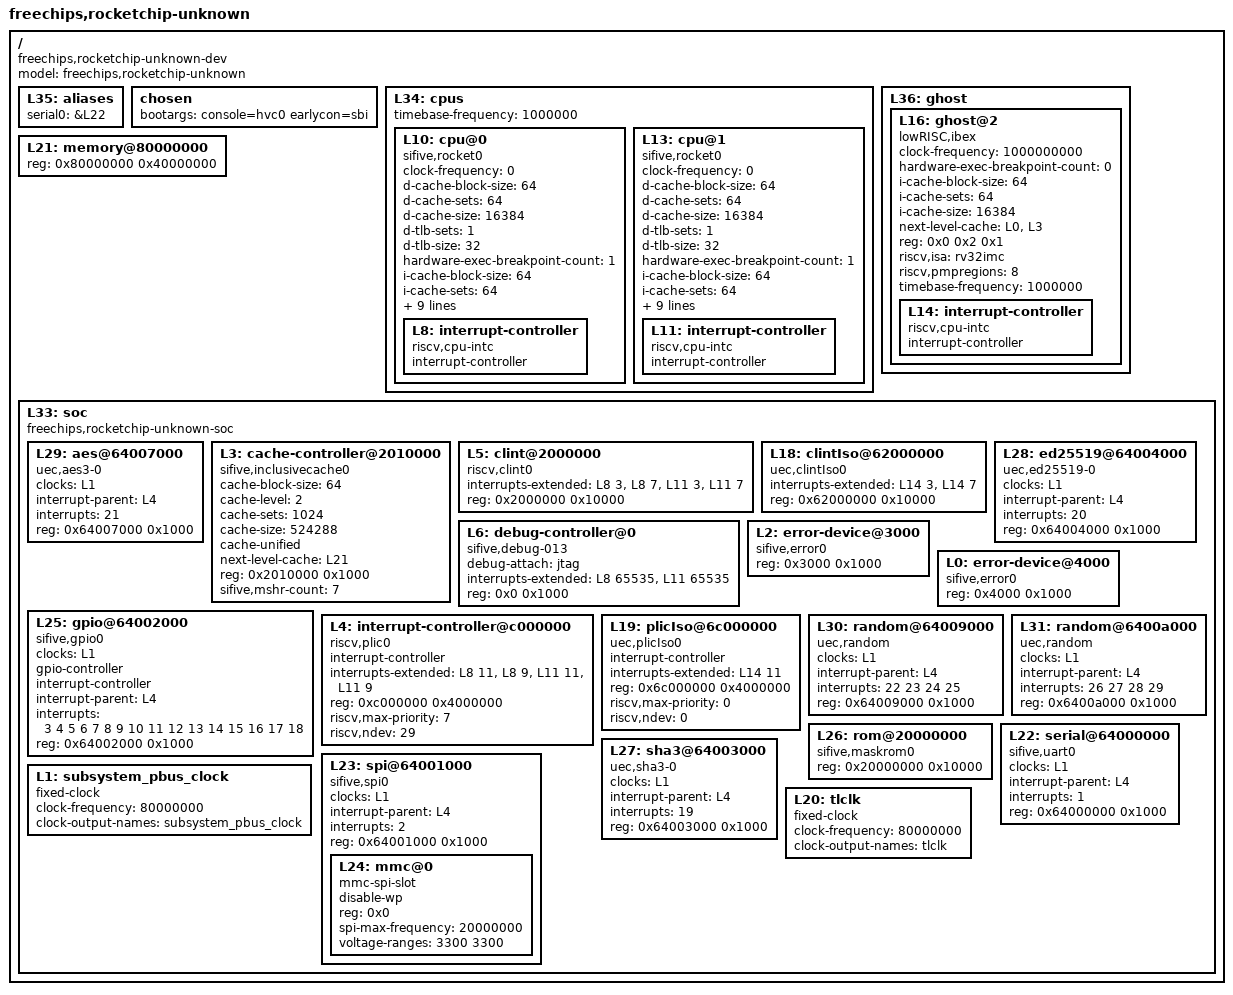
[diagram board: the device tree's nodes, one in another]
/*
 * I hate you, RISC-V linux.
 * A possible solution to avoid the dtc over the forced CMDARGS is to modify fdt.c... yeah....
 * And this is just for the chosen stuff. I hate you.
 */

/dts-v1/;

/ {
	#address-cells = <1>;
	#size-cells = <1>;
	compatible = "freechips,rocketchip-unknown-dev";
	model = "freechips,rocketchip-unknown";
	L35: aliases {
		serial0 = &L22;
	};
	chosen {
    bootargs = "console=hvc0 earlycon=sbi";
	};
	L34: cpus {
		#address-cells = <1>;
		#size-cells = <0>;
	  timebase-frequency = <1000000>;
		L10: cpu@0 {
			clock-frequency = <0>;
			compatible = "sifive,rocket0", "riscv";
			d-cache-block-size = <64>;
			d-cache-sets = <64>;
			d-cache-size = <16384>;
			d-tlb-sets = <1>;
			d-tlb-size = <32>;
			device_type = "cpu";
			hardware-exec-breakpoint-count = <1>;
			i-cache-block-size = <64>;
			i-cache-sets = <64>;
			i-cache-size = <16384>;
			i-tlb-sets = <1>;
			i-tlb-size = <32>;
			mmu-type = "riscv,sv39";
			next-level-cache = <&L0 &L3>;
			reg = <0x0>;
			riscv,isa = "rv64imafdc";
			riscv,pmpregions = <8>;
			status = "okay";
			tlb-split;
			L8: interrupt-controller {
				#interrupt-cells = <1>;
				compatible = "riscv,cpu-intc";
				interrupt-controller;
			};
		};
		L13: cpu@1 {
			clock-frequency = <0>;
			compatible = "sifive,rocket0", "riscv";
			d-cache-block-size = <64>;
			d-cache-sets = <64>;
			d-cache-size = <16384>;
			d-tlb-sets = <1>;
			d-tlb-size = <32>;
			device_type = "cpu";
			hardware-exec-breakpoint-count = <1>;
			i-cache-block-size = <64>;
			i-cache-sets = <64>;
			i-cache-size = <16384>;
			i-tlb-sets = <1>;
			i-tlb-size = <32>;
			mmu-type = "riscv,sv39";
			next-level-cache = <&L0 &L3>;
			reg = <0x1>;
			riscv,isa = "rv64imafdc";
			riscv,pmpregions = <8>;
			status = "okay";
			tlb-split;
			L11: interrupt-controller {
				#interrupt-cells = <1>;
				compatible = "riscv,cpu-intc";
				interrupt-controller;
			};
		};
	};
	L36: ghost {
		L16: ghost@2 {
			clock-frequency = <1000000000>;
			compatible = "lowRISC,ibex", "riscv";
			device_type = "ghost";
			hardware-exec-breakpoint-count = <0>;
			i-cache-block-size = <64>;
			i-cache-sets = <64>;
			i-cache-size = <16384>;
			next-level-cache = <&L0 &L3>;
			reg = <0x0 0x2 0x1>;
			riscv,isa = "rv32imc";
			riscv,pmpregions = <8>;
			status = "okay";
			timebase-frequency = <1000000>;
			L14: interrupt-controller {
				#interrupt-cells = <1>;
				compatible = "riscv,cpu-intc";
				interrupt-controller;
			};
		};
	};
	L21: memory@80000000 {
		device_type = "memory";
		reg = <0x80000000 0x40000000>;
	};
	L33: soc {
		#address-cells = <1>;
		#size-cells = <1>;
		compatible = "freechips,rocketchip-unknown-soc", "simple-bus";
		ranges;
		L29: aes@64007000 {
			clocks = <&L1>;
			compatible = "uec,aes3-0";
			interrupt-parent = <&L4>;
			interrupts = <21>;
			reg = <0x64007000 0x1000>;
			reg-names = "control";
		};
		L3: cache-controller@2010000 {
			cache-block-size = <64>;
			cache-level = <2>;
			cache-sets = <1024>;
			cache-size = <524288>;
			cache-unified;
			compatible = "sifive,inclusivecache0", "cache";
			next-level-cache = <&L21>;
			reg = <0x2010000 0x1000>;
			reg-names = "control";
			sifive,mshr-count = <7>;
		};
		L5: clint@2000000 {
			compatible = "riscv,clint0";
			interrupts-extended = <&L8 3 &L8 7 &L11 3 &L11 7>;
			reg = <0x2000000 0x10000>;
			reg-names = "control";
		};
		L18: clintIso@62000000 {
			compatible = "uec,clintIso0";
			interrupts-extended = <&L14 3 &L14 7>;
			reg = <0x62000000 0x10000>;
			reg-names = "control";
		};
		L6: debug-controller@0 {
			compatible = "sifive,debug-013", "riscv,debug-013";
			debug-attach = "jtag";
			interrupts-extended = <&L8 65535 &L11 65535>;
			reg = <0x0 0x1000>;
			reg-names = "control";
		};
		L28: ed25519@64004000 {
			clocks = <&L1>;
			compatible = "uec,ed25519-0";
			interrupt-parent = <&L4>;
			interrupts = <20>;
			reg = <0x64004000 0x1000>;
			reg-names = "control";
		};
		L2: error-device@3000 {
			compatible = "sifive,error0";
			reg = <0x3000 0x1000>;
		};
		L0: error-device@4000 {
			compatible = "sifive,error0";
			reg = <0x4000 0x1000>;
		};
		L25: gpio@64002000 {
			#gpio-cells = <2>;
			#interrupt-cells = <2>;
			clocks = <&L1>;
			compatible = "sifive,gpio0", "sifive,gpio1";
			gpio-controller;
			interrupt-controller;
			interrupt-parent = <&L4>;
			interrupts = <3 4 5 6 7 8 9 10 11 12 13 14 15 16 17 18>;
			reg = <0x64002000 0x1000>;
			reg-names = "control";
		};
		L4: interrupt-controller@c000000 {
			#interrupt-cells = <1>;
			compatible = "riscv,plic0";
			interrupt-controller;
			interrupts-extended = <&L8 11 &L8 9 &L11 11 &L11 9>;
			reg = <0xc000000 0x4000000>;
			reg-names = "control";
			riscv,max-priority = <7>;
			riscv,ndev = <29>;
		};
		L19: plicIso@6c000000 {
			#interrupt-cells = <1>;
			compatible = "uec,plicIso0";
			interrupt-controller;
			interrupts-extended = <&L14 11>;
			reg = <0x6c000000 0x4000000>;
			reg-names = "control";
			riscv,max-priority = <0>;
			riscv,ndev = <0>;
		};
		L30: random@64009000 {
			clocks = <&L1>;
			compatible = "uec,random";
			interrupt-parent = <&L4>;
			interrupts = <22 23 24 25>;
			reg = <0x64009000 0x1000>;
			reg-names = "control";
		};
		L31: random@6400a000 {
			clocks = <&L1>;
			compatible = "uec,random";
			interrupt-parent = <&L4>;
			interrupts = <26 27 28 29>;
			reg = <0x6400a000 0x1000>;
			reg-names = "control";
		};
		L26: rom@20000000 {
			compatible = "sifive,maskrom0";
			reg = <0x20000000 0x10000>;
			reg-names = "mem";
		};
		L22: serial@64000000 {
			clocks = <&L1>;
			compatible = "sifive,uart0";
			interrupt-parent = <&L4>;
			interrupts = <1>;
			reg = <0x64000000 0x1000>;
			reg-names = "control";
		};
		L27: sha3@64003000 {
			clocks = <&L1>;
			compatible = "uec,sha3-0";
			interrupt-parent = <&L4>;
			interrupts = <19>;
			reg = <0x64003000 0x1000>;
			reg-names = "control";
		};
		L23: spi@64001000 {
			#address-cells = <1>;
			#size-cells = <0>;
			clocks = <&L1>;
			compatible = "sifive,spi0";
			interrupt-parent = <&L4>;
			interrupts = <2>;
			reg = <0x64001000 0x1000>;
			reg-names = "control";
			L24: mmc@0 {
				compatible = "mmc-spi-slot";
				disable-wp;
				reg = <0x0>;
				spi-max-frequency = <20000000>;
				voltage-ranges = <3300 3300>;
			};
		};
		L1: subsystem_pbus_clock {
			#clock-cells = <0>;
			clock-frequency = <80000000>;
			clock-output-names = "subsystem_pbus_clock";
			compatible = "fixed-clock";
		};
		L20: tlclk {
			#clock-cells = <0>;
			clock-frequency = <80000000>;
			clock-output-names = "tlclk";
			compatible = "fixed-clock";
		};
	};
};
